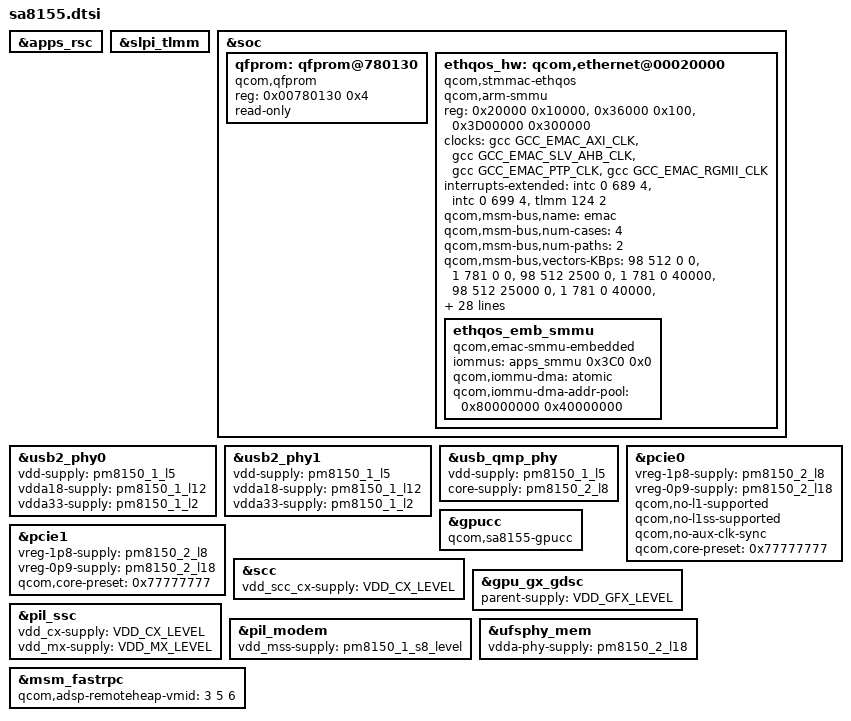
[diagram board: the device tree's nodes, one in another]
#include <dt-bindings/gpio/gpio.h>

/* Remove regulator nodes specific to SM8150 */
&apps_rsc {
	/delete-node/ regulator-pm8150-s4;
	/delete-node/ rpmh-regulator-msslvl;
	/delete-node/ rpmh-regulator-smpa2;
	/delete-node/ rpmh-regulator-ebilvl;
	/delete-node/ rpmh-regulator-smpa5;
	/delete-node/ rpmh-regulator-smpa6;
	/delete-node/ rpmh-regulator-ldoa1;
	/delete-node/ rpmh-regulator-ldoa2;
	/delete-node/ rpmh-regulator-ldoa3;
	/delete-node/ rpmh-regulator-lmxlvl;
	/delete-node/ rpmh-regulator-ldoa5;
	/delete-node/ rpmh-regulator-ldoa6;
	/delete-node/ rpmh-regulator-ldoa7;
	/delete-node/ rpmh-regulator-lcxlvl;
	/delete-node/ rpmh-regulator-ldoa9;
	/delete-node/ rpmh-regulator-ldoa10;
	/delete-node/ rpmh-regulator-ldoa11;
	/delete-node/ rpmh-regulator-ldoa12;
	/delete-node/ rpmh-regulator-ldoa13;
	/delete-node/ rpmh-regulator-ldoa14;
	/delete-node/ rpmh-regulator-ldoa15;
	/delete-node/ rpmh-regulator-ldoa16;
	/delete-node/ rpmh-regulator-ldoa17;
	/delete-node/ rpmh-regulator-smpc1;
	/delete-node/ rpmh-regulator-gfxlvl;
	/delete-node/ rpmh-regulator-mxlvl;
	/delete-node/ rpmh-regulator-mmcxlvl;
	/delete-node/ rpmh-regulator-cxlvl;
	/delete-node/ rpmh-regulator-smpc8;
	/delete-node/ rpmh-regulator-ldoc1;
	/delete-node/ rpmh-regulator-ldoc2;
	/delete-node/ rpmh-regulator-ldoc3;
	/delete-node/ rpmh-regulator-ldoc4;
	/delete-node/ rpmh-regulator-ldoc5;
	/delete-node/ rpmh-regulator-ldoc6;
	/delete-node/ rpmh-regulator-ldoc7;
	/delete-node/ rpmh-regulator-ldoc8;
	/delete-node/ rpmh-regulator-ldoc9;
	/delete-node/ rpmh-regulator-ldoc10;
	/delete-node/ rpmh-regulator-ldoc11;
	/delete-node/ rpmh-regulator-bobc1;
	/delete-node/ rpmh-regulator-smpf2;
	/delete-node/ rpmh-regulator-ldof2;
	/delete-node/ rpmh-regulator-ldof5;
	/delete-node/ rpmh-regulator-ldof6;
};

&slpi_tlmm {
	status = "ok";
};

&soc {
	qfprom: qfprom@780130 {
		compatible = "qcom,qfprom";
		reg = <0x00780130 0x4>;
		#address-cells = <1>;
		#size-cells = <1>;
		read-only;
		ranges;
	};
	ethqos_hw: qcom,ethernet@00020000 {
		compatible = "qcom,stmmac-ethqos";
		qcom,arm-smmu;
		reg = <0x20000 0x10000>,
			<0x36000 0x100>,
			<0x3D00000 0x300000>;
		reg-names = "stmmaceth", "rgmii","tlmm-central-base";
		clocks = <&gcc GCC_EMAC_AXI_CLK>,
			<&gcc GCC_EMAC_SLV_AHB_CLK>,
			<&gcc GCC_EMAC_PTP_CLK>,
			<&gcc GCC_EMAC_RGMII_CLK>;
		clock-names = "stmmaceth", "pclk", "ptp_ref", "rgmii";
		interrupts-extended = <&intc 0 689 4>, <&intc 0 699 4>,
			<&tlmm 124 2>;
		interrupt-names = "macirq", "eth_lpi",
			"phy-intr";
		qcom,msm-bus,name = "emac";
		qcom,msm-bus,num-cases = <4>;
		qcom,msm-bus,num-paths = <2>;
		qcom,msm-bus,vectors-KBps =
			<98 512 0 0>, <1 781 0 0>, /* No vote */
			<98 512 2500 0>, <1 781 0 40000>, /* 10Mbps vote */
			<98 512 25000 0>, <1 781 0 40000>, /* 100Mbps vote */
			<98 512 250000 0>, <1 781 0 40000>; /* 1000Mbps vote */
		qcom,bus-vector-names = "0", "10", "100", "1000";
		snps,tso;
		rx-fifo-depth = <4096>;
		tx-fifo-depth = <4096>;
		snps,reset-gpios = <&tlmm 79 GPIO_ACTIVE_HIGH>;
		qcom,phy-intr-redirect = <&tlmm 124 GPIO_ACTIVE_LOW>;
		gdsc_emac-supply = <&emac_gdsc>;

		pinctrl-names = "dev-emac-mdc",
			"dev-emac-mdio",
			"dev-emac-rgmii_txd0_state",
			"dev-emac-rgmii_txd1_state",
			"dev-emac-rgmii_txd2_state",
			"dev-emac-rgmii_txd3_state",
			"dev-emac-rgmii_txc_state",
			"dev-emac-rgmii_tx_ctl_state",
			"dev-emac-rgmii_rxd0_state",
			"dev-emac-rgmii_rxd1_state",
			"dev-emac-rgmii_rxd2_state",
			"dev-emac-rgmii_rxd3_state",
			"dev-emac-rgmii_rxc_state",
			"dev-emac-rgmii_rx_ctl_state",
			"dev-emac-phy_intr",
			"dev-emac-phy_reset_state",
			"dev-emac_pin_pps_0";

		pinctrl-0 = <&emac_mdc>;
		pinctrl-1 = <&emac_mdio>;

		pinctrl-2 = <&emac_rgmii_txd0>;
		pinctrl-3 = <&emac_rgmii_txd1>;
		pinctrl-4 = <&emac_rgmii_txd2>;
		pinctrl-5 = <&emac_rgmii_txd3>;
		pinctrl-6 = <&emac_rgmii_txc>;
		pinctrl-7 = <&emac_rgmii_tx_ctl>;

		pinctrl-8 = <&emac_rgmii_rxd0>;
		pinctrl-9 = <&emac_rgmii_rxd1>;
		pinctrl-10 = <&emac_rgmii_rxd2>;
		pinctrl-11 = <&emac_rgmii_rxd3>;
		pinctrl-12 = <&emac_rgmii_rxc>;
		pinctrl-13 = <&emac_rgmii_rx_ctl>;

		pinctrl-14 = <&emac_phy_intr>;
		pinctrl-15 = <&emac_phy_reset_state>;
		pinctrl-16 = <&emac_pin_pps_0>;

		snps,reset-delays-us = <0 11000 70000>;
		phy-mode = "rgmii";

		ethqos_emb_smmu: ethqos_emb_smmu {
			compatible = "qcom,emac-smmu-embedded";
			iommus = <&apps_smmu 0x3C0 0x0>;
			qcom,iommu-dma = "atomic";
			qcom,iommu-dma-addr-pool = <0x80000000 0x40000000>;
		};
	};

};

&usb2_phy0 {
	vdd-supply = <&pm8150_1_l5>;
	vdda18-supply = <&pm8150_1_l12>;
	vdda33-supply = <&pm8150_1_l2>;
};

&usb2_phy1 {
	vdd-supply = <&pm8150_1_l5>;
	vdda18-supply = <&pm8150_1_l12>;
	vdda33-supply = <&pm8150_1_l2>;
};

&usb_qmp_phy {
	vdd-supply = <&pm8150_1_l5>;
	core-supply = <&pm8150_2_l8>;
};

/* Add regulator nodes specific to SA8155 */
#include "sa8155-regulator.dtsi"

&pcie0 {
	vreg-1p8-supply = <&pm8150_2_l8>;
	vreg-0p9-supply = <&pm8150_2_l18>;
	qcom,no-l1-supported;
	qcom,no-l1ss-supported;
	qcom,no-aux-clk-sync;
	qcom,core-preset = <0x77777777>;
};

&pcie1 {
	vreg-1p8-supply = <&pm8150_2_l8>;
	vreg-0p9-supply = <&pm8150_2_l18>;
	qcom,core-preset = <0x77777777>;
};

&gpucc {
	compatible = "qcom,sa8155-gpucc", "syscon";
};

&scc {
	vdd_scc_cx-supply = <&VDD_CX_LEVEL>;
	status = "ok";
};

&gpu_gx_gdsc {
	parent-supply = <&VDD_GFX_LEVEL>;
};

&pil_ssc {
	vdd_cx-supply = <&VDD_CX_LEVEL>;
	vdd_mx-supply = <&VDD_MX_LEVEL>;
};

&pil_modem {
	vdd_mss-supply = <&pm8150_1_s8_level>;
};

&ufsphy_mem {
	vdda-phy-supply = <&pm8150_2_l18>;
};

&msm_fastrpc {
	qcom,adsp-remoteheap-vmid = <3 5 6>;
};

#include "camera/sa8155-camera.dtsi"
#include "camera/sa8155-camera-sensor.dtsi"
#include "sa8155-audio.dtsi"
